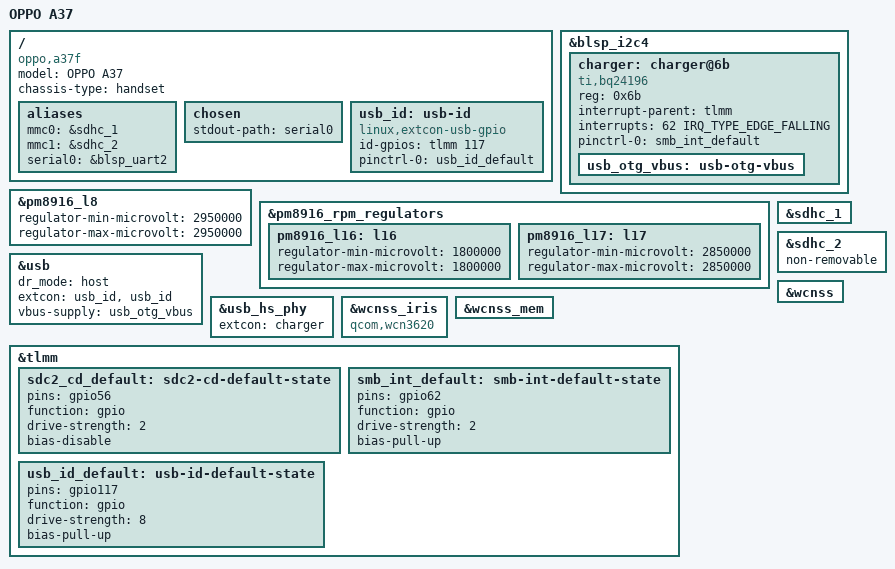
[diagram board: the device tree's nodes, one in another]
// SPDX-License-Identifier: GPL-2.0-only

/dts-v1/;

#include "msm8916-pm8916.dtsi"
#include <dt-bindings/gpio/gpio.h>
#include <dt-bindings/interrupt-controller/irq.h>

/ {
	model = "OPPO A37";
	compatible = "oppo,a37f", "qcom,msm8916";
	chassis-type = "handset";

	aliases {
		mmc0 = &sdhc_1;
		mmc1 = &sdhc_2;
		serial0 = &blsp_uart2;
	};

	chosen {
		stdout-path = "serial0";
	};

	usb_id: usb-id {
		compatible = "linux,extcon-usb-gpio";
		id-gpios = <&tlmm 117 GPIO_ACTIVE_HIGH>;
		pinctrl-names = "default";
		pinctrl-0 = <&usb_id_default>;
	};
};

&blsp_i2c4 {
	status = "okay";

	charger: charger@6b {
		compatible = "ti,bq24196";
		reg = <0x6b>;

		interrupt-parent = <&tlmm>;
		interrupts = <62 IRQ_TYPE_EDGE_FALLING>;

		pinctrl-names = "default";
		pinctrl-0 = <&smb_int_default>;

		usb_otg_vbus: usb-otg-vbus {
		};
	};
};

&pm8916_l8 {
	regulator-min-microvolt = <2950000>;
	regulator-max-microvolt = <2950000>;
};

&pm8916_rpm_regulators {
	pm8916_l16: l16 {
		regulator-min-microvolt = <1800000>;
		regulator-max-microvolt = <1800000>;
	};

	pm8916_l17: l17 {
		regulator-min-microvolt = <2850000>;
		regulator-max-microvolt = <2850000>;
	};
};

&sdhc_1 {
	status = "okay";
};

&sdhc_2 {
	status = "okay";
	non-removable;
};

&usb {
	status = "okay";
	dr_mode ="host";
	extcon = <&usb_id>, <&usb_id>;
	vbus-supply = <&usb_otg_vbus>;
};

&usb_hs_phy {
	extcon = <&charger>;
};

&wcnss {
	status = "okay";
};

&wcnss_iris {
	compatible = "qcom,wcn3620";
};

&wcnss_mem {
	status = "okay";
};

&tlmm {
	sdc2_cd_default: sdc2-cd-default-state {
		pins = "gpio56";
		function = "gpio";

		drive-strength = <2>;
		bias-disable;
	};

	smb_int_default: smb-int-default-state {
		pins = "gpio62";
		function = "gpio";

		drive-strength = <2>;
		bias-pull-up;
	};

	usb_id_default: usb-id-default-state {
		pins = "gpio117";
		function = "gpio";

		drive-strength = <8>;
		bias-pull-up;
	};
};
